# TLE987x register map
Vendor: Infineon; Series: MOTIX MCU; File version: 4.2
CPU: CM3 r0p0, little endian, no MPU, no FPU, 4 interrupt priority bits
Registers are 32-bit, read-write, reset 0x0 unless marked. A register's access mark holds for its fields unless they carry their own. Offsets are from the block's base; [hi:lo] are bit positions; 'fields as' and 'values as' point back to an identical list.

## TIMER2 — TIMER2 Module
Base 0x48004000
Same registers: TIMER21 0x48005000
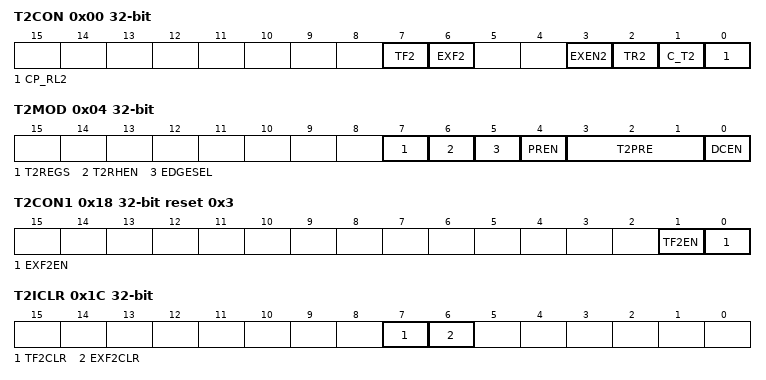
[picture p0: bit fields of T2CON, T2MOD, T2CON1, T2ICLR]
0x00 T2CON access per field — Timer 2 Control Register
  [7] TF2 ro — Timer 2 Overflow/Underflow Flag
  [6] EXF2 ro — Timer 2 External Flag
  [3] EXEN2 rw — Timer 2 External Enable Control
    0=External events are disabled; 1=External events are enabled in Capture/Reload Mode
  [2] TR2 rw — Timer 2 Start/Stop Control
    0=Stop Timer 2; 1=Start Timer 2
  [1] C_T2 rw — Timer or Counter Select
    0=Timer function selected; 1=Count upon negative edge at pin T2
  [0] CP_RL2 rw — Capture/Reload Select
    0=Reload upon overflow or upon negative/positive transition at pin T2EX (when EXEN2 = 1); 1=Capture Timer 2 data register contents on the negative/positive transition at pin T2EX, provided EXEN2 = 1.The negative or positive transition at Pin T2EX is selected by bit EDGESEL
0x04 T2MOD — Timer 2 Mode Register
  [7] T2REGS — Edge Select for Timer 2 External Start
    0=The falling edge at Pin T2EX is selected; 1=The rising edge at Pin T2EX is selected
  [6] T2RHEN — Timer 2 External Start Enable
    0=Timer 2 External Start is disabled; 1=Timer 2 External Start is enabled
  [5] EDGESEL — Edge Select in Capture Mode/Reload Mode
    values as T2REGS
  [4] PREN — Prescaler Enable
    0=Prescaler is disabled and the 2 or 12 divider takes effect; 1=Prescaler is enabled (see T2PRE bit) and the 2 or 12 divider is bypassed
  [3:1] T2PRE — Timer 2 Prescaler Bit
    0=fT2 = fPCLK; 1=fT2 = fPCLK / 2; 2=fT2 = fPCLK / 4; 3=fT2 = fPCLK / 8; 4=fT2 = fPCLK / 16; 5=fT2 = fPCLK / 32; 6=fT2 = fPCLK / 64; 7=fT2 = fPCLK / 128
  [0] DCEN — Up/Down Counter Enable
    0=Up/Down Counter function is disabled; 1=Up/Down Counter function is enabled and controlled by pin T2EX (Up = 1, Down = 0)
0x08 RC2L — Timer 2 Reload/Capture Register, Low Byte
  [7:0] RC2 — Reload/Capture Value
0x0C RC2H — Timer 2 Reload/Capture Register, High Byte
  [7:0] RC2 — Reload/Capture Value
0x10 T2L — Timer 2, Low Byte
  [7:0] T2L — Timer 2 Value
0x14 T2H — Timer 2, High Byte
  [7:0] T2H — Timer 2 Value
0x18 T2CON1 reset 0x3 — Timer 2 Control Register 1
  [1] TF2EN — Overflow/Underflow Interrupt Enable
    0=Overflow/underflow interrupt is disabled; 1=Overflow/underflow interrupt is enabled
  [0] EXF2EN — External Interrupt Enable
    0=External interrupt is disabled; 1=External interrupt is enabled
0x1C T2ICLR wo — Timer 2 Interrupt Clear Register
  [7] TF2CLR — Overflow/Underflow Interrupt Clear Flag
    0=Overflow/underflow interrupt is not cleared; 1=Overflow/underflow interrupt is cleared
  [6] EXF2CLR — External Interrupt Clear Flag
    0=External interrupt is not cleared; 1=External interrupt is cleared

## UART1 — UART1 Module
Base 0x48020000
Same registers: UART2 0x48022000
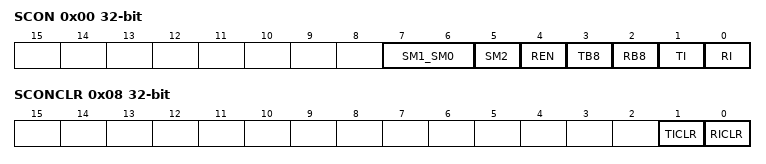
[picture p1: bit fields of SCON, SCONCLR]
0x00 SCON — Serial Channel Control Register
  [7:6] SM1_SM0 — Serial Port Operating Mode Selection
    0=Mode 0: 8-bit shift register, fixed baud rate (fPCLK/2); 1=Mode 1: 8-bit UART, variable baud rate; 2=Mode 2: 9-bit UART, fixed baud rate (fPCLK/64 or fPCLK/32); 3=Mode 3: 9-bit UART, variable baud rate
  [5] SM2 — Enable Serial Port Multiprocessor Communication in Modes 2 and 3
  [4] REN — Enable Receiver of Serial Port
    0=Serial reception is disabled; 1=Serial reception is enabled
  [3] TB8 — Serial Port Transmitter Bit 9
  [2] RB8 — Serial Port Receiver Bit 9
  [1] TI — Transmit Interrupt Flag
  [0] RI — Receive Interrupt Flag
0x04 SBUF — Serial Data Buffer
  [7:0] VAL — Serial Interface Buffer Register
0x08 SCONCLR wo — Serial Channel Control Clear Register
  [1] TICLR — Transmit Interrupt Clear Flag
  [0] RICLR — Receive Interrupt Clear Flag
